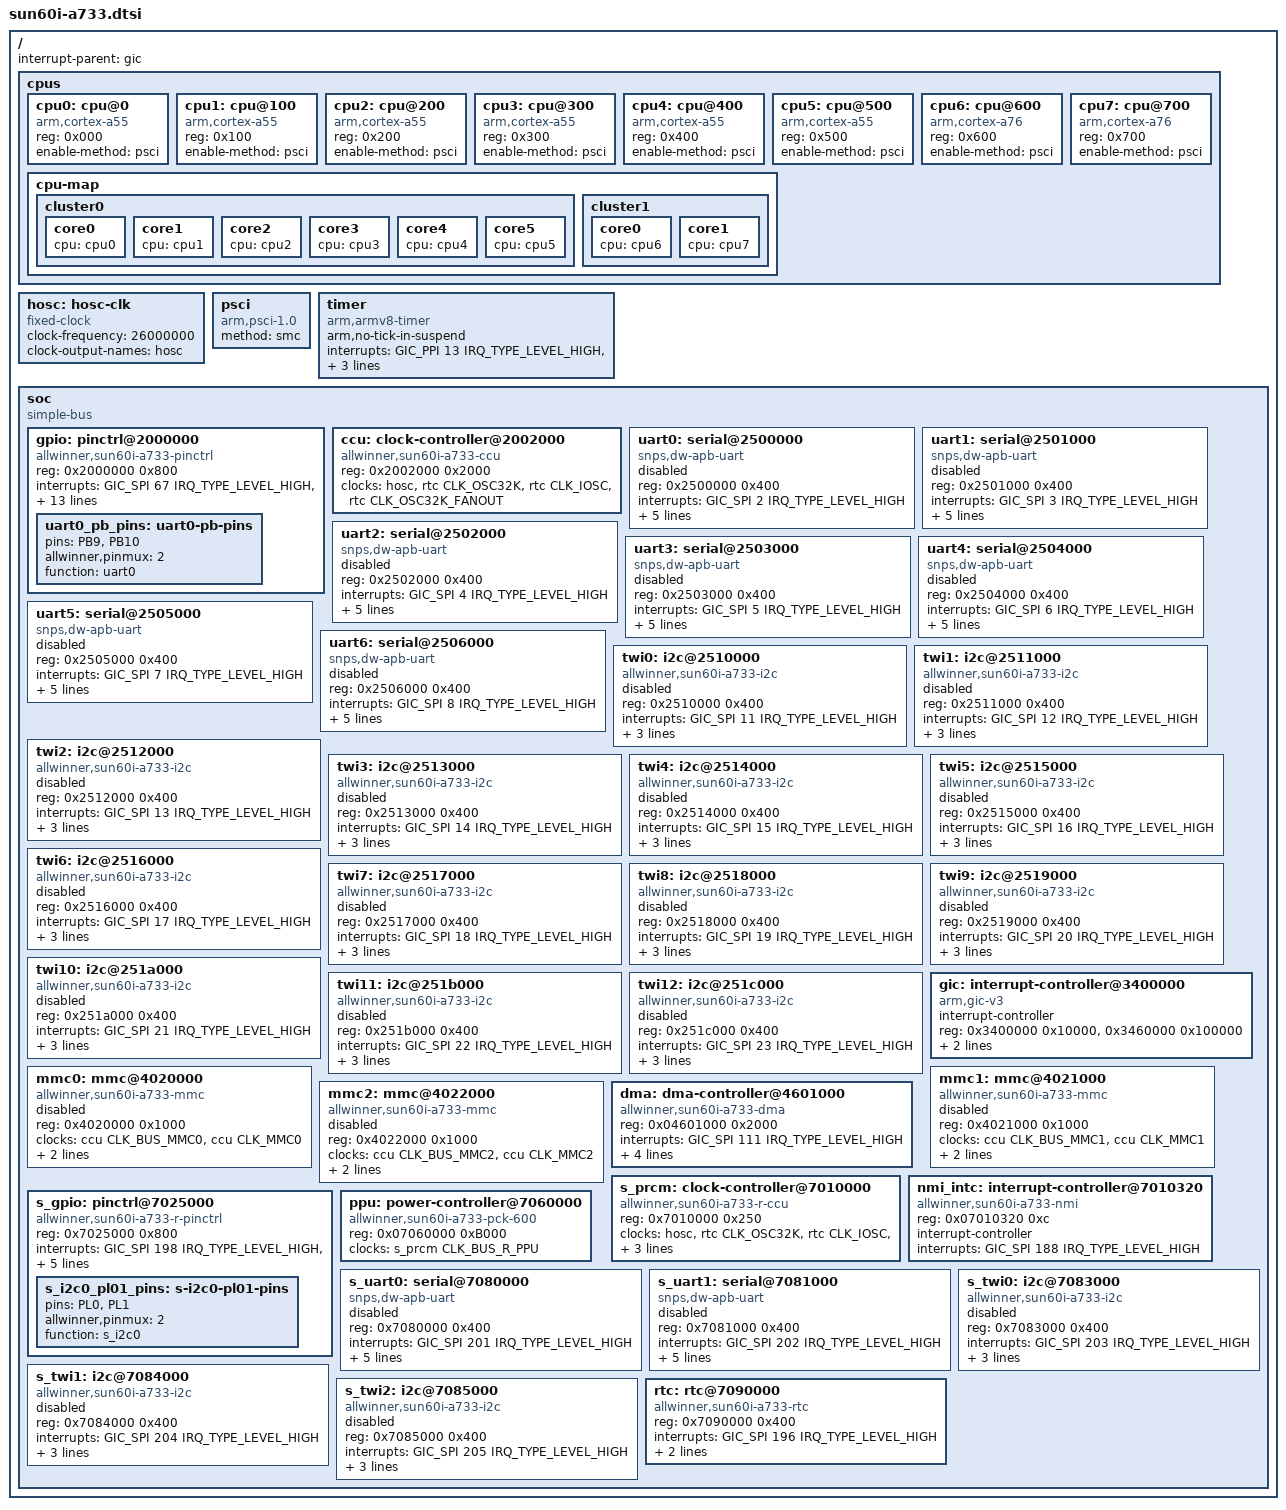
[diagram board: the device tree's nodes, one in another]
// SPDX-License-Identifier: (GPL-2.0-only OR MIT)
// Copyright (C) 2026 Jerome Brunet <jbrunet@baylibre.com>


#include <dt-bindings/interrupt-controller/arm-gic.h>
#include <dt-bindings/clock/sun6i-rtc.h>
#include <dt-bindings/clock/allwinner,sun60i-a733-ccu.h>
#include <dt-bindings/clock/allwinner,sun60i-a733-r-ccu.h>
#include <dt-bindings/reset/allwinner,sun60i-a733-ccu.h>
#include <dt-bindings/reset/allwinner,sun60i-a733-r-ccu.h>

/ {
	interrupt-parent = <&gic>;
	#address-cells = <2>;
	#size-cells = <2>;

	cpus {
		#address-cells = <1>;
		#size-cells = <0>;

		cpu0: cpu@0 {
			compatible = "arm,cortex-a55";
			device_type = "cpu";
			reg = <0x000>;
			enable-method = "psci";
		};

		cpu1: cpu@100 {
			compatible = "arm,cortex-a55";
			device_type = "cpu";
			reg = <0x100>;
			enable-method = "psci";
		};

		cpu2: cpu@200 {
			compatible = "arm,cortex-a55";
			device_type = "cpu";
			reg = <0x200>;
			enable-method = "psci";
		};

		cpu3: cpu@300 {
			compatible = "arm,cortex-a55";
			device_type = "cpu";
			reg = <0x300>;
			enable-method = "psci";
		};

		cpu4: cpu@400 {
			compatible = "arm,cortex-a55";
			device_type = "cpu";
			reg = <0x400>;
			enable-method = "psci";
		};

		cpu5: cpu@500 {
			compatible = "arm,cortex-a55";
			device_type = "cpu";
			reg = <0x500>;
			enable-method = "psci";
		};

		cpu6: cpu@600 {
			compatible = "arm,cortex-a76";
			device_type = "cpu";
			reg = <0x600>;
			enable-method = "psci";
		};

		cpu7: cpu@700 {
			compatible = "arm,cortex-a76";
			device_type = "cpu";
			reg = <0x700>;
			enable-method = "psci";
		};

		cpu-map {
			cluster0 {
				core0 {
					cpu = <&cpu0>;
				};

				core1 {
					cpu = <&cpu1>;
				};

				core2 {
					cpu = <&cpu2>;
				};

				core3 {
					cpu = <&cpu3>;
				};

				core4 {
					cpu = <&cpu4>;
				};

				core5 {
					cpu = <&cpu5>;
				};
			};

			cluster1 {
				core0 {
					cpu = <&cpu6>;
				};

				core1 {
					cpu = <&cpu7>;
				};
			};
		};
	};

	hosc: hosc-clk {
		#clock-cells = <0>;
		compatible = "fixed-clock";
		clock-frequency = <26000000>;
		clock-output-names = "hosc";
	};

	psci {
		compatible = "arm,psci-1.0";
		method = "smc";
	};

	timer {
		compatible = "arm,armv8-timer";
		arm,no-tick-in-suspend;
		interrupts = <GIC_PPI 13 IRQ_TYPE_LEVEL_HIGH>,
			     <GIC_PPI 14 IRQ_TYPE_LEVEL_HIGH>,
			     <GIC_PPI 11 IRQ_TYPE_LEVEL_HIGH>,
			     <GIC_PPI 10 IRQ_TYPE_LEVEL_HIGH>;
	};

	soc {
		compatible = "simple-bus";
		#address-cells = <1>;
		#size-cells = <1>;
		ranges = <0x0 0x0 0x0 0x40000000>;

		gpio: pinctrl@2000000 {
			compatible = "allwinner,sun60i-a733-pinctrl";
			reg = <0x2000000 0x800>;
			interrupts = <GIC_SPI 67 IRQ_TYPE_LEVEL_HIGH>,
				     <GIC_SPI 69 IRQ_TYPE_LEVEL_HIGH>,
				     <GIC_SPI 71 IRQ_TYPE_LEVEL_HIGH>,
				     <GIC_SPI 73 IRQ_TYPE_LEVEL_HIGH>,
				     <GIC_SPI 75 IRQ_TYPE_LEVEL_HIGH>,
				     <GIC_SPI 77 IRQ_TYPE_LEVEL_HIGH>,
				     <GIC_SPI 79 IRQ_TYPE_LEVEL_HIGH>,
				     <GIC_SPI 81 IRQ_TYPE_LEVEL_HIGH>,
				     <GIC_SPI 83 IRQ_TYPE_LEVEL_HIGH>,
				     <GIC_SPI 85 IRQ_TYPE_LEVEL_HIGH>,
				     <GIC_SPI 87 IRQ_TYPE_LEVEL_HIGH>;
			clocks = <&ccu CLK_APB1>, <&hosc>, <&rtc CLK_OSC32K>;
			clock-names = "apb", "hosc", "losc";
			gpio-controller;
			#gpio-cells = <3>;
			interrupt-controller;
			#interrupt-cells = <3>;

			/omit-if-no-ref/
			uart0_pb_pins: uart0-pb-pins {
				pins = "PB9", "PB10";
				allwinner,pinmux = <2>;
				function = "uart0";
			};
		};

		ccu: clock-controller@2002000 {
			compatible = "allwinner,sun60i-a733-ccu";
			reg = <0x2002000 0x2000>;
			clocks = <&hosc>, <&rtc CLK_OSC32K>,
				 <&rtc CLK_IOSC>, <&rtc CLK_OSC32K_FANOUT>;
			clock-names = "hosc", "losc",
				      "iosc", "losc-fanout";
			#clock-cells = <1>;
			#reset-cells = <1>;
		};

		uart0: serial@2500000 {
			compatible = "snps,dw-apb-uart";
			reg = <0x2500000 0x400>;
			interrupts = <GIC_SPI 2 IRQ_TYPE_LEVEL_HIGH>;
			reg-shift = <2>;
			reg-io-width = <4>;
			clocks = <&ccu CLK_BUS_UART0>;
			resets = <&ccu RST_BUS_UART0>;
			dmas = <&dma 14>, <&dma 14>;
			dma-names = "tx", "rx";
			status = "disabled";
		};

		uart1: serial@2501000 {
			compatible = "snps,dw-apb-uart";
			reg = <0x2501000 0x400>;
			interrupts = <GIC_SPI 3 IRQ_TYPE_LEVEL_HIGH>;
			reg-shift = <2>;
			reg-io-width = <4>;
			clocks = <&ccu CLK_BUS_UART1>;
			resets = <&ccu RST_BUS_UART1>;
			dmas = <&dma 15>, <&dma 15>;
			dma-names = "tx", "rx";
			status = "disabled";
		};

		uart2: serial@2502000 {
			compatible = "snps,dw-apb-uart";
			reg = <0x2502000 0x400>;
			interrupts = <GIC_SPI 4 IRQ_TYPE_LEVEL_HIGH>;
			reg-shift = <2>;
			reg-io-width = <4>;
			clocks = <&ccu CLK_BUS_UART2>;
			resets = <&ccu RST_BUS_UART2>;
			dmas = <&dma 16>, <&dma 16>;
			dma-names = "tx", "rx";
			status = "disabled";
		};

		uart3: serial@2503000 {
			compatible = "snps,dw-apb-uart";
			reg = <0x2503000 0x400>;
			interrupts = <GIC_SPI 5 IRQ_TYPE_LEVEL_HIGH>;
			reg-shift = <2>;
			reg-io-width = <4>;
			clocks = <&ccu CLK_BUS_UART3>;
			resets = <&ccu RST_BUS_UART3>;
			dmas = <&dma 17>, <&dma 17>;
			dma-names = "tx", "rx";
			status = "disabled";
		};

		uart4: serial@2504000 {
			compatible = "snps,dw-apb-uart";
			reg = <0x2504000 0x400>;
			interrupts = <GIC_SPI 6 IRQ_TYPE_LEVEL_HIGH>;
			reg-shift = <2>;
			reg-io-width = <4>;
			clocks = <&ccu CLK_BUS_UART4>;
			resets = <&ccu RST_BUS_UART4>;
			dmas = <&dma 18>, <&dma 18>;
			dma-names = "tx", "rx";
			status = "disabled";
		};

		uart5: serial@2505000 {
			compatible = "snps,dw-apb-uart";
			reg = <0x2505000 0x400>;
			interrupts = <GIC_SPI 7 IRQ_TYPE_LEVEL_HIGH>;
			reg-shift = <2>;
			reg-io-width = <4>;
			clocks = <&ccu CLK_BUS_UART5>;
			resets = <&ccu RST_BUS_UART5>;
			dmas = <&dma 19>, <&dma 19>;
			dma-names = "tx", "rx";
			status = "disabled";
		};

		uart6: serial@2506000 {
			compatible = "snps,dw-apb-uart";
			reg = <0x2506000 0x400>;
			interrupts = <GIC_SPI 8 IRQ_TYPE_LEVEL_HIGH>;
			reg-shift = <2>;
			reg-io-width = <4>;
			clocks = <&ccu CLK_BUS_UART6>;
			resets = <&ccu RST_BUS_UART6>;
			dmas = <&dma 20>, <&dma 20>;
			dma-names = "tx", "rx";
			status = "disabled";
		};

		twi0: i2c@2510000 {
			compatible = "allwinner,sun60i-a733-i2c",
				     "allwinner,sun8i-v536-i2c",
				     "allwinner,sun6i-a31-i2c";
			reg = <0x2510000 0x400>;
			interrupts = <GIC_SPI 11 IRQ_TYPE_LEVEL_HIGH>;
			clocks = <&ccu CLK_BUS_I2C0>;
			resets = <&ccu RST_BUS_I2C0>;
			dmas = <&dma 37>, <&dma 37>;
			dma-names = "rx", "tx";
			status = "disabled";
			#address-cells = <1>;
			#size-cells = <0>;
		};

		twi1: i2c@2511000 {
			compatible = "allwinner,sun60i-a733-i2c",
				     "allwinner,sun8i-v536-i2c",
				     "allwinner,sun6i-a31-i2c";
			reg = <0x2511000 0x400>;
			interrupts = <GIC_SPI 12 IRQ_TYPE_LEVEL_HIGH>;
			clocks = <&ccu CLK_BUS_I2C1>;
			resets = <&ccu RST_BUS_I2C1>;
			dmas = <&dma 38>, <&dma 38>;
			dma-names = "rx", "tx";
			status = "disabled";
			#address-cells = <1>;
			#size-cells = <0>;
		};

		twi2: i2c@2512000 {
			compatible = "allwinner,sun60i-a733-i2c",
				     "allwinner,sun8i-v536-i2c",
				     "allwinner,sun6i-a31-i2c";
			reg = <0x2512000 0x400>;
			interrupts = <GIC_SPI 13 IRQ_TYPE_LEVEL_HIGH>;
			clocks = <&ccu CLK_BUS_I2C2>;
			resets = <&ccu RST_BUS_I2C2>;
			dmas = <&dma 39>, <&dma 39>;
			dma-names = "rx", "tx";
			status = "disabled";
			#address-cells = <1>;
			#size-cells = <0>;
		};

		twi3: i2c@2513000 {
			compatible = "allwinner,sun60i-a733-i2c",
				     "allwinner,sun8i-v536-i2c",
				     "allwinner,sun6i-a31-i2c";
			reg = <0x2513000 0x400>;
			interrupts = <GIC_SPI 14 IRQ_TYPE_LEVEL_HIGH>;
			clocks = <&ccu CLK_BUS_I2C3>;
			resets = <&ccu RST_BUS_I2C3>;
			dmas = <&dma 40>, <&dma 40>;
			dma-names = "rx", "tx";
			status = "disabled";
			#address-cells = <1>;
			#size-cells = <0>;
		};

		twi4: i2c@2514000 {
			compatible = "allwinner,sun60i-a733-i2c",
				     "allwinner,sun8i-v536-i2c",
				     "allwinner,sun6i-a31-i2c";
			reg = <0x2514000 0x400>;
			interrupts = <GIC_SPI 15 IRQ_TYPE_LEVEL_HIGH>;
			clocks = <&ccu CLK_BUS_I2C4>;
			resets = <&ccu RST_BUS_I2C4>;
			dmas = <&dma 41>, <&dma 41>;
			dma-names = "rx", "tx";
			status = "disabled";
			#address-cells = <1>;
			#size-cells = <0>;
		};

		twi5: i2c@2515000 {
			compatible = "allwinner,sun60i-a733-i2c",
				     "allwinner,sun8i-v536-i2c",
				     "allwinner,sun6i-a31-i2c";
			reg = <0x2515000 0x400>;
			interrupts = <GIC_SPI 16 IRQ_TYPE_LEVEL_HIGH>;
			clocks = <&ccu CLK_BUS_I2C5>;
			resets = <&ccu RST_BUS_I2C5>;
			dmas = <&dma 42>, <&dma 42>;
			dma-names = "rx", "tx";
			status = "disabled";
			#address-cells = <1>;
			#size-cells = <0>;
		};

		twi6: i2c@2516000 {
			compatible = "allwinner,sun60i-a733-i2c",
				     "allwinner,sun8i-v536-i2c",
				     "allwinner,sun6i-a31-i2c";
			reg = <0x2516000 0x400>;
			interrupts = <GIC_SPI 17 IRQ_TYPE_LEVEL_HIGH>;
			clocks = <&ccu CLK_BUS_I2C6>;
			resets = <&ccu RST_BUS_I2C6>;
			dmas = <&dma 43>, <&dma 43>;
			dma-names = "rx", "tx";
			status = "disabled";
			#address-cells = <1>;
			#size-cells = <0>;
		};

		twi7: i2c@2517000 {
			compatible = "allwinner,sun60i-a733-i2c",
				     "allwinner,sun8i-v536-i2c",
				     "allwinner,sun6i-a31-i2c";
			reg = <0x2517000 0x400>;
			interrupts = <GIC_SPI 18 IRQ_TYPE_LEVEL_HIGH>;
			clocks = <&ccu CLK_BUS_I2C7>;
			resets = <&ccu RST_BUS_I2C7>;
			dmas = <&dma 44>, <&dma 44>;
			dma-names = "rx", "tx";
			status = "disabled";
			#address-cells = <1>;
			#size-cells = <0>;
		};

		twi8: i2c@2518000 {
			compatible = "allwinner,sun60i-a733-i2c",
				     "allwinner,sun8i-v536-i2c",
				     "allwinner,sun6i-a31-i2c";
			reg = <0x2518000 0x400>;
			interrupts = <GIC_SPI 19 IRQ_TYPE_LEVEL_HIGH>;
			clocks = <&ccu CLK_BUS_I2C8>;
			resets = <&ccu RST_BUS_I2C8>;
			dmas = <&dma 45>, <&dma 45>;
			dma-names = "rx", "tx";
			status = "disabled";
			#address-cells = <1>;
			#size-cells = <0>;
		};

		twi9: i2c@2519000 {
			compatible = "allwinner,sun60i-a733-i2c",
				     "allwinner,sun8i-v536-i2c",
				     "allwinner,sun6i-a31-i2c";
			reg = <0x2519000 0x400>;
			interrupts = <GIC_SPI 20 IRQ_TYPE_LEVEL_HIGH>;
			clocks = <&ccu CLK_BUS_I2C9>;
			resets = <&ccu RST_BUS_I2C9>;
			dmas = <&dma 58>, <&dma 58>;
			dma-names = "rx", "tx";
			status = "disabled";
			#address-cells = <1>;
			#size-cells = <0>;
		};

		twi10: i2c@251a000 {
			compatible = "allwinner,sun60i-a733-i2c",
				     "allwinner,sun8i-v536-i2c",
				     "allwinner,sun6i-a31-i2c";
			reg = <0x251a000 0x400>;
			interrupts = <GIC_SPI 21 IRQ_TYPE_LEVEL_HIGH>;
			clocks = <&ccu CLK_BUS_I2C10>;
			resets = <&ccu RST_BUS_I2C10>;
			dmas = <&dma 59>, <&dma 59>;
			dma-names = "rx", "tx";
			status = "disabled";
			#address-cells = <1>;
			#size-cells = <0>;
		};

		twi11: i2c@251b000 {
			compatible = "allwinner,sun60i-a733-i2c",
				     "allwinner,sun8i-v536-i2c",
				     "allwinner,sun6i-a31-i2c";
			reg = <0x251b000 0x400>;
			interrupts = <GIC_SPI 22 IRQ_TYPE_LEVEL_HIGH>;
			clocks = <&ccu CLK_BUS_I2C11>;
			resets = <&ccu RST_BUS_I2C11>;
			dmas = <&dma 60>, <&dma 60>;
			dma-names = "rx", "tx";
			status = "disabled";
			#address-cells = <1>;
			#size-cells = <0>;
		};

		twi12: i2c@251c000 {
			compatible = "allwinner,sun60i-a733-i2c",
				     "allwinner,sun8i-v536-i2c",
				     "allwinner,sun6i-a31-i2c";
			reg = <0x251c000 0x400>;
			interrupts = <GIC_SPI 23 IRQ_TYPE_LEVEL_HIGH>;
			clocks = <&ccu CLK_BUS_I2C12>;
			resets = <&ccu RST_BUS_I2C12>;
			dmas = <&dma 61>, <&dma 61>;
			dma-names = "rx", "tx";
			status = "disabled";
			#address-cells = <1>;
			#size-cells = <0>;
		};

		gic: interrupt-controller@3400000 {
			compatible = "arm,gic-v3";
			#address-cells = <1>;
			#interrupt-cells = <3>;
			#size-cells = <1>;
			ranges;
			interrupt-controller;
			reg = <0x3400000 0x10000>,
			      <0x3460000 0x100000>;
			interrupts = <GIC_PPI 9 IRQ_TYPE_LEVEL_HIGH>;
			dma-noncoherent;

			/* its: msi-controller@3440000 { */
			/* 	compatible = "arm,gic-v3-its"; */
			/* 	reg = <0x3440000 0x20000>; */
			/* 	msi-controller; */
			/* 	#msi-cells = <1>; */
			/* 	dma-noncoherent; */
			/* }; */
		};

		mmc0: mmc@4020000 {
			compatible = "allwinner,sun60i-a733-mmc",
				     "allwinner,sun20i-d1-mmc";
			reg = <0x4020000 0x1000>;
			clocks = <&ccu CLK_BUS_MMC0>, <&ccu CLK_MMC0>;
			clock-names = "ahb", "mmc";
			resets = <&ccu RST_BUS_MMC0>;
			reset-names = "ahb";
			interrupts = <GIC_SPI 161 IRQ_TYPE_LEVEL_HIGH>;
			status = "disabled";
			#address-cells = <1>;
			#size-cells = <0>;
		};

		mmc1: mmc@4021000 {
			compatible = "allwinner,sun60i-a733-mmc",
				     "allwinner,sun20i-d1-mmc";
			reg = <0x4021000 0x1000>;
			clocks = <&ccu CLK_BUS_MMC1>, <&ccu CLK_MMC1>;
			clock-names = "ahb", "mmc";
			resets = <&ccu RST_BUS_MMC1>;
			reset-names = "ahb";
			interrupts = <GIC_SPI 162 IRQ_TYPE_LEVEL_HIGH>;
			status = "disabled";
			#address-cells = <1>;
			#size-cells = <0>;
		};

		mmc2: mmc@4022000 {
			compatible = "allwinner,sun60i-a733-mmc",
				     "allwinner,sun20i-d1-mmc";
			reg = <0x4022000 0x1000>;
			clocks = <&ccu CLK_BUS_MMC2>, <&ccu CLK_MMC2>;
			clock-names = "ahb", "mmc";
			resets = <&ccu RST_BUS_MMC2>;
			reset-names = "ahb";
			interrupts = <GIC_SPI 163 IRQ_TYPE_LEVEL_HIGH>;
			status = "disabled";
			#address-cells = <1>;
			#size-cells = <0>;
		};

		dma: dma-controller@4601000 {
			compatible = "allwinner,sun60i-a733-dma";
			reg = <0x04601000 0x2000>;
			interrupts = <GIC_SPI 111 IRQ_TYPE_LEVEL_HIGH>;
			clocks = <&ccu CLK_BUS_DMA0>, <&ccu CLK_MBUS_DMA0>;
			clock-names = "bus", "mbus";
			dma-channels = <16>;
			dma-requests = <64>;
			resets = <&ccu RST_BUS_DMA0>;
			#dma-cells = <1>;
		};

		s_prcm: clock-controller@7010000 {
			compatible = "allwinner,sun60i-a733-r-ccu";
			reg = <0x7010000 0x250>;
			clocks = <&hosc>,
				 <&rtc CLK_OSC32K>,
				 <&rtc CLK_IOSC>,
				 <&ccu CLK_SYS_24M>,
				 <&ccu CLK_PLL_PERIPH0_200M>,
				 <&ccu CLK_PLL_PERIPH0_300M>,
				 <&ccu CLK_PLL_PERIPH1_300M>;
			clock-names = "hosc",
				      "losc",
				      "iosc",
				      "sys-24m",
				      "pll-periph0-200m",
				      "pll-periph0-300m",
				      "pll-periph1-300m";
			#clock-cells = <1>;
			#reset-cells = <1>;
		};

		nmi_intc: interrupt-controller@7010320 {
			compatible = "allwinner,sun60i-a733-nmi",
				     "allwinner,sun55i-a523-nmi";
			reg = <0x07010320 0xc>;
			interrupt-controller;
			#interrupt-cells = <2>;
			interrupts = <GIC_SPI 188 IRQ_TYPE_LEVEL_HIGH>;
		};

		s_gpio: pinctrl@7025000 {
			compatible = "allwinner,sun60i-a733-r-pinctrl";
			reg = <0x7025000 0x800>;
			interrupts = <GIC_SPI 198 IRQ_TYPE_LEVEL_HIGH>,
				     <GIC_SPI 200 IRQ_TYPE_LEVEL_HIGH>;
			clocks = <&s_prcm CLK_R_APB0>,
				 <&hosc>,
				 <&rtc CLK_OSC32K>;
			clock-names = "apb", "hosc", "losc";
			gpio-controller;
			#gpio-cells = <3>;
			interrupt-controller;
			#interrupt-cells = <3>;

			/omit-if-no-ref/
			s_i2c0_pl01_pins: s-i2c0-pl01-pins {
				pins = "PL0", "PL1";
				allwinner,pinmux = <2>;
				function = "s_i2c0";
			};
		};

		ppu: power-controller@7060000 {
			compatible = "allwinner,sun60i-a733-pck-600";
			reg = <0x07060000 0xB000>;
			clocks = <&s_prcm CLK_BUS_R_PPU>;
			#power-domain-cells = <1>;
		};

		s_uart0: serial@7080000 {
			compatible = "snps,dw-apb-uart";
			reg = <0x7080000 0x400>;
			interrupts = <GIC_SPI 201 IRQ_TYPE_LEVEL_HIGH>;
			reg-shift = <2>;
			reg-io-width = <4>;
			clocks = <&s_prcm CLK_BUS_R_UART0>;
			resets = <&s_prcm RST_BUS_R_UART0>;
			dmas = <&dma 50>, <&dma 50>;
			dma-names = "tx", "rx";
			status = "disabled";
		};

		s_uart1: serial@7081000 {
			compatible = "snps,dw-apb-uart";
			reg = <0x7081000 0x400>;
			interrupts = <GIC_SPI 202 IRQ_TYPE_LEVEL_HIGH>;
			reg-shift = <2>;
			reg-io-width = <4>;
			clocks = <&s_prcm CLK_BUS_R_UART1>;
			resets = <&s_prcm RST_BUS_R_UART1>;
			dmas = <&dma 51>, <&dma 51>;
			dma-names = "tx", "rx";
			status = "disabled";
		};

		s_twi0: i2c@7083000 {
			compatible = "allwinner,sun60i-a733-i2c",
				     "allwinner,sun8i-v536-i2c",
				     "allwinner,sun6i-a31-i2c";
			reg = <0x7083000 0x400>;
			interrupts = <GIC_SPI 203 IRQ_TYPE_LEVEL_HIGH>;
			clocks = <&s_prcm CLK_BUS_R_I2C0>;
			resets = <&s_prcm RST_BUS_R_I2C0>;
			dmas = <&dma 47>, <&dma 47>;
			dma-names = "rx", "tx";
			status = "disabled";
			#address-cells = <1>;
			#size-cells = <0>;
		};

		s_twi1: i2c@7084000 {
			compatible = "allwinner,sun60i-a733-i2c",
				     "allwinner,sun8i-v536-i2c",
				     "allwinner,sun6i-a31-i2c";
			reg = <0x7084000 0x400>;
			interrupts = <GIC_SPI 204 IRQ_TYPE_LEVEL_HIGH>;
			clocks = <&s_prcm CLK_BUS_R_I2C1>;
			resets = <&s_prcm RST_BUS_R_I2C1>;
			dmas = <&dma 48>, <&dma 48>;
			dma-names = "rx", "tx";
			status = "disabled";
			#address-cells = <1>;
			#size-cells = <0>;
		};

		s_twi2: i2c@7085000 {
			compatible = "allwinner,sun60i-a733-i2c",
				     "allwinner,sun8i-v536-i2c",
				     "allwinner,sun6i-a31-i2c";
			reg = <0x7085000 0x400>;
			interrupts = <GIC_SPI 205 IRQ_TYPE_LEVEL_HIGH>;
			clocks = <&s_prcm CLK_BUS_R_I2C2>;
			resets = <&s_prcm RST_BUS_R_I2C2>;
			dmas = <&dma 49>, <&dma 49>;
			dma-names = "rx", "tx";
			status = "disabled";
			#address-cells = <1>;
			#size-cells = <0>;
		};

		rtc: rtc@7090000 {
			compatible = "allwinner,sun60i-a733-rtc",
				     "allwinner,sun50i-r329-rtc";
			reg = <0x7090000 0x400>;
			interrupts = <GIC_SPI 196 IRQ_TYPE_LEVEL_HIGH>;
			clocks = <&s_prcm CLK_BUS_R_RTC>,
				 <&hosc>,
				 <&s_prcm CLK_R_AHB>;
			clock-names = "bus", "hosc", "ahb";
			#clock-cells = <1>;
		};
	};
};
